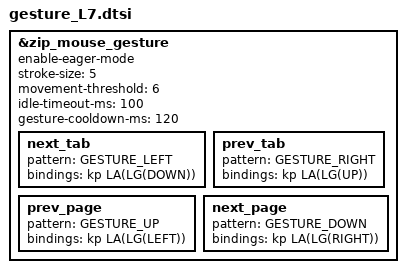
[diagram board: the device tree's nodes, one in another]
&zip_mouse_gesture {
    enable-eager-mode;
    stroke-size = <5>;
    movement-threshold = <6>;
    idle-timeout-ms = <100>;
    gesture-cooldown-ms = <120>;

    next_tab    { pattern = <GESTURE_LEFT>;  bindings = <&kp LA(LG(DOWN))>; };
    prev_tab    { pattern = <GESTURE_RIGHT>; bindings = <&kp LA(LG(UP))>; };
    prev_page  { pattern = <GESTURE_UP>;    bindings = <&kp LA(LG(LEFT))>; };
    next_page   { pattern = <GESTURE_DOWN>;  bindings = <&kp LA(LG(RIGHT))>; };
};
